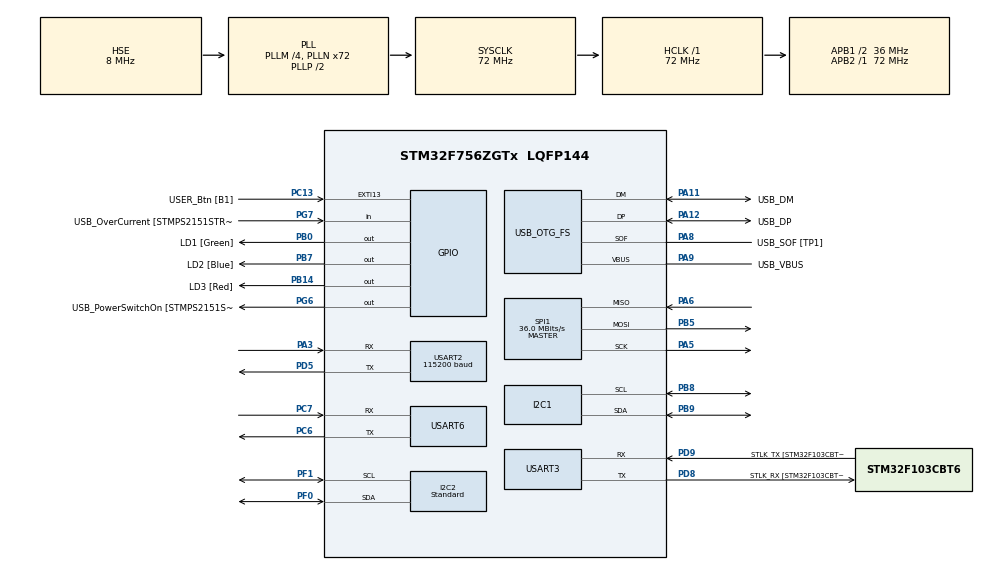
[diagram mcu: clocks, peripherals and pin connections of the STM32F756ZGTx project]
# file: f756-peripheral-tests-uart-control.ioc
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Dma.I2C1_RX.2.Direction=DMA_PERIPH_TO_MEMORY
Dma.I2C1_RX.2.FIFOMode=DMA_FIFOMODE_DISABLE
Dma.I2C1_RX.2.Instance=DMA1_Stream0
Dma.I2C1_RX.2.MemDataAlignment=DMA_MDATAALIGN_BYTE
Dma.I2C1_RX.2.MemInc=DMA_MINC_ENABLE
Dma.I2C1_RX.2.Mode=DMA_NORMAL
Dma.I2C1_RX.2.PeriphDataAlignment=DMA_PDATAALIGN_BYTE
Dma.I2C1_RX.2.PeriphInc=DMA_PINC_DISABLE
Dma.I2C1_RX.2.Priority=DMA_PRIORITY_LOW
Dma.I2C1_TX.3.Direction=DMA_MEMORY_TO_PERIPH
Dma.I2C1_TX.3.FIFOMode=DMA_FIFOMODE_DISABLE
Dma.I2C1_TX.3.Instance=DMA1_Stream6
Dma.I2C1_TX.3.MemDataAlignment=DMA_MDATAALIGN_BYTE
Dma.I2C1_TX.3.MemInc=DMA_MINC_ENABLE
Dma.I2C1_TX.3.Mode=DMA_NORMAL
Dma.I2C1_TX.3.PeriphDataAlignment=DMA_PDATAALIGN_BYTE
Dma.I2C1_TX.3.PeriphInc=DMA_PINC_DISABLE
Dma.I2C1_TX.3.Priority=DMA_PRIORITY_LOW
Dma.I2C2_RX.1.Direction=DMA_PERIPH_TO_MEMORY
Dma.I2C2_RX.1.FIFOMode=DMA_FIFOMODE_DISABLE
Dma.I2C2_RX.1.Instance=DMA1_Stream3
Dma.I2C2_RX.1.MemDataAlignment=DMA_MDATAALIGN_BYTE
Dma.I2C2_RX.1.MemInc=DMA_MINC_ENABLE
Dma.I2C2_RX.1.Mode=DMA_NORMAL
Dma.I2C2_RX.1.PeriphDataAlignment=DMA_PDATAALIGN_BYTE
Dma.I2C2_RX.1.PeriphInc=DMA_PINC_DISABLE
Dma.I2C2_RX.1.Priority=DMA_PRIORITY_LOW
Dma.I2C2_TX.0.Direction=DMA_MEMORY_TO_PERIPH
Dma.I2C2_TX.0.FIFOMode=DMA_FIFOMODE_DISABLE
Dma.I2C2_TX.0.Instance=DMA1_Stream7
Dma.I2C2_TX.0.MemDataAlignment=DMA_MDATAALIGN_BYTE
Dma.I2C2_TX.0.MemInc=DMA_MINC_ENABLE
Dma.I2C2_TX.0.Mode=DMA_NORMAL
Dma.I2C2_TX.0.PeriphDataAlignment=DMA_PDATAALIGN_BYTE
Dma.I2C2_TX.0.PeriphInc=DMA_PINC_DISABLE
Dma.I2C2_TX.0.Priority=DMA_PRIORITY_LOW
Dma.Request0=I2C2_TX
Dma.Request1=I2C2_RX
Dma.Request2=I2C1_RX
Dma.Request3=I2C1_TX
FREERTOS.Tasks01=defaultTask,24,128,StartDefaultTask,Default,NULL,Static,defaultTaskBuffer,defaultTaskControlBlock;UARTListenTask,8,128,StartUARTListenTask,Default,NULL,Static,UARTListenTaskBuffer,UARTListenTaskControlBlock;UARTTestTask,8,128,StartUARTTestTask,Default,NULL,Static,UARTTestTaskBuffer,UARTTestTaskControlBlock;I2CTestTask,8,128,StartI2CTestTask,Default,NULL,Static,I2CTestTaskBuffer,I2CTestTaskControlBlock;SPITestTask,8,128,StartSPITestTask,Default,NULL,Static,SPITestTaskBuffer,SPITestTaskControlBlock
FREERTOS.configUSE_NEWLIB_REENTRANT=1
I2C1.GeneralCallMode=I2C_GENERALCALL_ENABLE
I2C1.OwnAddress=0x0A
I2C1.Timing=0x00808CD2
I2C2.DualAddressMode=I2C_DUALADDRESS_DISABLE
I2C2.I2C_Speed_Mode=I2C_Standard
I2C2.OwnAddress=0x72
I2C2.Timing=0x00808CD2
Mcu.Family=STM32F7
Mcu.Name=STM32F756ZGTx
Mcu.Package=LQFP144
NVIC.DMA1_Stream0_IRQn=true\:5\:0\:false\:false\:true\:true\:false\:true\:true
NVIC.DMA1_Stream3_IRQn=true\:5\:0\:false\:false\:true\:true\:false\:true\:true
NVIC.DMA1_Stream6_IRQn=true\:5\:0\:false\:false\:true\:true\:false\:true\:true
NVIC.DMA1_Stream7_IRQn=true\:5\:0\:false\:false\:true\:true\:false\:true\:true
NVIC.EXTI15_10_IRQn=true\:5\:0\:false\:false\:true\:true\:true\:true\:true
NVIC.I2C1_ER_IRQn=true\:5\:0\:false\:false\:true\:true\:true\:true\:true
NVIC.I2C1_EV_IRQn=true\:5\:0\:false\:false\:true\:true\:true\:true\:true
NVIC.I2C2_ER_IRQn=true\:5\:0\:false\:false\:true\:true\:true\:true\:true
NVIC.I2C2_EV_IRQn=true\:5\:0\:false\:false\:true\:true\:true\:true\:true
NVIC.PriorityGroup=NVIC_PRIORITYGROUP_4
NVIC.TIM2_IRQn=true\:15\:0\:false\:false\:true\:false\:false\:true\:true
NVIC.TimeBase=TIM2_IRQn
NVIC.TimeBaseIP=TIM2
NVIC.USART6_IRQn=true\:5\:0\:false\:false\:true\:true\:true\:true\:true
PA1.GPIO_Label=RMII_REF_CLK [LAN8742A-CZ-TR_REFCLK0]
PA1.Signal=ETH_REF_CLK
PA10.GPIO_Label=USB_ID
PA10.Signal=USB_OTG_FS_ID
PA11.GPIO_Label=USB_DM
PA11.Mode=Device_Only
PA11.Signal=USB_OTG_FS_DM
PA12.GPIO_Label=USB_DP
PA12.Mode=Device_Only
PA12.Signal=USB_OTG_FS_DP
PA13.GPIO_Label=TMS
PA13.Mode=Serial_Wire
PA13.Signal=SYS_JTMS-SWDIO
PA14.GPIO_Label=TCK
PA14.Mode=Serial_Wire
PA14.Signal=SYS_JTCK-SWCLK
PA2.GPIO_Label=RMII_MDIO [LAN8742A-CZ-TR_MDIO]
PA2.Signal=ETH_MDIO
PA3.GPIO_PuPd=GPIO_NOPULL
PA3.Mode=Asynchronous
PA3.Signal=USART2_RX
PA5.Mode=Full_Duplex_Master
PA5.Signal=SPI1_SCK
PA6.Mode=Full_Duplex_Master
PA6.Signal=SPI1_MISO
PA7.GPIO_Label=RMII_CRS_DV [LAN8742A-CZ-TR_CRS_DV]
PA7.Signal=ETH_CRS_DV
PA8.GPIO_Label=USB_SOF [TP1]
PA8.Mode=Activate_SOF_FS
PA8.Signal=USB_OTG_FS_SOF
PA9.GPIO_Label=USB_VBUS
PA9.Mode=Activate_VBUS
PA9.Signal=USB_OTG_FS_VBUS
PB0.GPIO_Label=LD1 [Green]
PB0.Signal=GPIO_Output
PB13.GPIO_Label=RMII_TXD1 [LAN8742A-CZ-TR_TXD1]
PB13.Signal=ETH_TXD1
PB14.GPIO_Label=LD3 [Red]
PB14.Signal=GPIO_Output
PB3.GPIO_Label=SW0
PB3.Signal=SYS_JTDO-SWO
PB5.Mode=Full_Duplex_Master
PB5.Signal=SPI1_MOSI
PB7.GPIO_Label=LD2 [Blue]
PB7.Signal=GPIO_Output
PB8.GPIO_Pu=GPIO_PULLUP
PB8.Mode=I2C
PB8.Signal=I2C1_SCL
PB9.GPIO_Pu=GPIO_PULLUP
PB9.Mode=I2C
PB9.Signal=I2C1_SDA
PC1.GPIO_Label=RMII_MDC [LAN8742A-CZ-TR_MDC]
PC1.Signal=ETH_MDC
PC13.GPIO_Label=USER_Btn [B1]
PC13.Signal=GPXTI13
PC14/OSC32_IN.Mode=LSE-External-Oscillator
PC14/OSC32_IN.Signal=RCC_OSC32_IN
PC15/OSC32_OUT.Mode=LSE-External-Oscillator
PC15/OSC32_OUT.Signal=RCC_OSC32_OUT
PC4.GPIO_Label=RMII_RXD0 [LAN8742A-CZ-TR_RXD0]
PC4.Signal=ETH_RXD0
PC5.GPIO_Label=RMII_RXD1 [LAN8742A-CZ-TR_RXD1]
PC5.Signal=ETH_RXD1
PC6.Mode=Asynchronous
PC6.Signal=USART6_TX
PC7.Mode=Asynchronous
PC7.Signal=USART6_RX
PD5.GPIO_PuPd=GPIO_NOPULL
PD5.Mode=Asynchronous
PD5.Signal=USART2_TX
PD8.GPIO_Label=STLK_RX [STM32F103CBT6_PA3]
PD8.Mode=Asynchronous
PD8.Signal=USART3_TX
PD9.GPIO_Label=STLK_TX [STM32F103CBT6_PA2]
PD9.Mode=Asynchronous
PD9.Signal=USART3_RX
PF0.GPIO_Pu=GPIO_PULLUP
PF0.Mode=I2C
PF0.Signal=I2C2_SDA
PF1.GPIO_Pu=GPIO_PULLUP
PF1.Mode=I2C
PF1.Signal=I2C2_SCL
PG11.GPIO_Label=RMII_TX_EN [LAN8742A-CZ-TR_TXEN]
PG11.Signal=ETH_TX_EN
PG13.GPIO_Label=RMII_TXD0 [LAN8742A-CZ-TR_TXD0]
PG13.Signal=ETH_TXD0
PG6.GPIO_Label=USB_PowerSwitchOn [STMPS2151STR_EN]
PG6.Signal=GPIO_Output
PG7.GPIO_Label=USB_OverCurrent [STMPS2151STR_FAULT]
PG7.Signal=GPIO_Input
PH0/OSC_IN.GPIO_Label=MCO [STM32F103CBT6_PA8]
PH0/OSC_IN.Mode=HSE-External-Clock-Source
PH0/OSC_IN.Signal=RCC_OSC_IN
PH1/OSC_OUT.Mode=HSE-External-Clock-Source
PH1/OSC_OUT.Signal=RCC_OSC_OUT
ProjectManager.HeapSize=0x200
ProjectManager.StackSize=0x400
ProjectManager.TargetToolchain=STM32CubeIDE
RCC.48MHZClocksFreq_Value=24000000
RCC.AHBFreq_Value=72000000
RCC.APB1CLKDivider=RCC_HCLK_DIV2
RCC.APB1Freq_Value=36000000
RCC.APB1TimFreq_Value=72000000
RCC.APB2Freq_Value=72000000
RCC.APB2TimFreq_Value=72000000
RCC.CortexFreq_Value=72000000
RCC.HCLKFreq_Value=72000000
RCC.HSE_VALUE=8000000
RCC.HSI_VALUE=16000000
RCC.PLLM=4
RCC.PLLMUL=RCC_PLL_MUL9
RCC.PLLN=72
RCC.PLLQ=3
RCC.PRESCALERUSB=RCC_USBCLKSOURCE_PLL_DIV1_5
RCC.SYSCLKFreq_VALUE=72000000
RCC.SYSCLKSource=RCC_SYSCLKSOURCE_PLLCLK
RCC.SYSCLKSourceVirtual=RCC_SYSCLKSOURCE_PLLCLK
RCC.USBFreq_Value=48000000
RCC.VCOOutputFreq_Value=144000000
SPI1.CalculateBaudRate=36.0 MBits/s
SPI1.DataSize=SPI_DATASIZE_8BIT
SPI1.Direction=SPI_DIRECTION_2LINES
SPI1.Mode=SPI_MODE_MASTER
SPI1.NSSPMode=SPI_NSS_PULSE_DISABLE
SPI1.VirtualType=VM_MASTER
USART2.AutoBaudRateEnableParam=UART_ADVFEATURE_AUTOBAUDRATE_DISABLE
USART2.BaudRate=115200
USART2.MSBFirstParam=ADVFEATURE_MSBFIRST_DISABLE
USART2.VirtualMode-Asynchronous=VM_ASYNC
USART3.VirtualMode-Asynchronous=VM_ASYNC
USART6.VirtualMode-Asynchronous=VM_ASYNC
USB_OTG_FS.VirtualMode=Device_Only
VP_FREERTOS_VS_CMSIS_V2.Mode=CMSIS_V2
VP_SYS_VS_tim2.Mode=TIM2
board=NUCLEO-F756ZG

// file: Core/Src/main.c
/* USER CODE BEGIN Header */
/**
  ******************************************************************************
  * @file           : main.c
  * @brief          : Main program body
  ******************************************************************************
  * @attention
  *
  * Copyright (c) 2025 STMicroelectronics.
  * All rights reserved.
  *
  * This software is licensed under terms that can be found in the LICENSE file
  * in the root directory of this software component.
  * If no LICENSE file comes with this software, it is provided AS-IS.
  *
  ******************************************************************************
  */
/* USER CODE END Header */
#include "main.h"
#include "cmsis_os.h"

typedef StaticTask_t osStaticThreadDef_t;

I2C_HandleTypeDef hi2c1;
I2C_HandleTypeDef hi2c2;
DMA_HandleTypeDef hdma_i2c1_rx;
DMA_HandleTypeDef hdma_i2c1_tx;
DMA_HandleTypeDef hdma_i2c2_tx;
DMA_HandleTypeDef hdma_i2c2_rx;

SPI_HandleTypeDef hspi1;

UART_HandleTypeDef huart2;
UART_HandleTypeDef huart3;
UART_HandleTypeDef huart6;

PCD_HandleTypeDef hpcd_USB_OTG_FS;

/* Definitions for defaultTask */
osThreadId_t defaultTaskHandle;
uint32_t defaultTaskBuffer[ 128 ];
osStaticThreadDef_t defaultTaskControlBlock;
const osThreadAttr_t defaultTask_attributes = {
  .name = "defaultTask",
  .cb_mem = &defaultTaskControlBlock,
  .cb_size = sizeof(defaultTaskControlBlock),
  .stack_mem = &defaultTaskBuffer[0],
  .stack_size = sizeof(defaultTaskBuffer),
  .priority = (osPriority_t) osPriorityNormal,
};
/* Definitions for UARTListenTask */
osThreadId_t UARTListenTaskHandle;
uint32_t UARTListenTaskBuffer[ 128 ];
osStaticThreadDef_t UARTListenTaskControlBlock;
const osThreadAttr_t UARTListenTask_attributes = {
  .name = "UARTListenTask",
  .cb_mem = &UARTListenTaskControlBlock,
  .cb_size = sizeof(UARTListenTaskControlBlock),
  .stack_mem = &UARTListenTaskBuffer[0],
  .stack_size = sizeof(UARTListenTaskBuffer),
  .priority = (osPriority_t) osPriorityLow,
};
/* Definitions for UARTTestTask */
osThreadId_t UARTTestTaskHandle;
uint32_t UARTTestTaskBuffer[ 128 ];
osStaticThreadDef_t UARTTestTaskControlBlock;
const osThreadAttr_t UARTTestTask_attributes = {
  .name = "UARTTestTask",
  .cb_mem = &UARTTestTaskControlBlock,
  .cb_size = sizeof(UARTTestTaskControlBlock),
  .stack_mem = &UARTTestTaskBuffer[0],
  .stack_size = sizeof(UARTTestTaskBuffer),
  .priority = (osPriority_t) osPriorityLow,
};
/* Definitions for I2CTestTask */
osThreadId_t I2CTestTaskHandle;
uint32_t I2CTestTaskBuffer[ 128 ];
osStaticThreadDef_t I2CTestTaskControlBlock;
const osThreadAttr_t I2CTestTask_attributes = {
  .name = "I2CTestTask",
  .cb_mem = &I2CTestTaskControlBlock,
  .cb_size = sizeof(I2CTestTaskControlBlock),
  .stack_mem = &I2CTestTaskBuffer[0],
  .stack_size = sizeof(I2CTestTaskBuffer),
  .priority = (osPriority_t) osPriorityLow,
};
/* Definitions for SPITestTask */
osThreadId_t SPITestTaskHandle;
uint32_t SPITestTaskBuffer[ 128 ];
osStaticThreadDef_t SPITestTaskControlBlock;
const osThreadAttr_t SPITestTask_attributes = {
  .name = "SPITestTask",
  .cb_mem = &SPITestTaskControlBlock,
  .cb_size = sizeof(SPITestTaskControlBlock),
  .stack_mem = &SPITestTaskBuffer[0],
  .stack_size = sizeof(SPITestTaskBuffer),
  .priority = (osPriority_t) osPriorityLow,
};

void SystemClock_Config(void);
static void MX_GPIO_Init(void);
static void MX_DMA_Init(void);
static void MX_USART3_UART_Init(void);
static void MX_USB_OTG_FS_PCD_Init(void);
static void MX_USART2_UART_Init(void);
static void MX_I2C2_Init(void);
static void MX_I2C1_Init(void);
static void MX_SPI1_Init(void);
static void MX_USART6_UART_Init(void);
void StartDefaultTask(void *argument);
void StartUARTListenTask(void *argument);
void StartUARTTestTask(void *argument);
void StartI2CTestTask(void *argument);
void StartSPITestTask(void *argument);

int main(void)
{

  /* MCU Configuration--------------------------------------------------------*/

  /* Reset of all peripherals, Initializes the Flash interface and the Systick. */
  HAL_Init();

  /* Configure the system clock */
  SystemClock_Config();

  /* Initialize all configured peripherals */
  MX_GPIO_Init();
  MX_DMA_Init();
  MX_USART3_UART_Init();
  MX_USB_OTG_FS_PCD_Init();
  MX_USART2_UART_Init();
  MX_I2C2_Init();
  MX_I2C1_Init();
  MX_SPI1_Init();
  MX_USART6_UART_Init();
  /* USER CODE BEGIN 2 */
  serial_uart_initialize();
  /* USER CODE END 2 */

  /* Init scheduler */
  osKernelInitialize();

  /* Create the thread(s) */
  /* creation of defaultTask */
  defaultTaskHandle = osThreadNew(StartDefaultTask, NULL, &defaultTask_attributes);

  /* creation of UARTListenTask */
  UARTListenTaskHandle = osThreadNew(StartUARTListenTask, NULL, &UARTListenTask_attributes);

  /* creation of UARTTestTask */
  UARTTestTaskHandle = osThreadNew(StartUARTTestTask, NULL, &UARTTestTask_attributes);

  /* creation of I2CTestTask */
  I2CTestTaskHandle = osThreadNew(StartI2CTestTask, NULL, &I2CTestTask_attributes);

  /* creation of SPITestTask */
  SPITestTaskHandle = osThreadNew(StartSPITestTask, NULL, &SPITestTask_attributes);

  /* Start scheduler */
  osKernelStart();

  /* We should never get here as control is now taken by the scheduler */

  /* Infinite loop */
  while (1)
  {

  }
}

void SystemClock_Config(void)
{
  RCC_OscInitTypeDef RCC_OscInitStruct = {0};
  RCC_ClkInitTypeDef RCC_ClkInitStruct = {0};

  /** Configure LSE Drive Capability
  */
  HAL_PWR_EnableBkUpAccess();

  /** Configure the main internal regulator output voltage
  */
  __HAL_RCC_PWR_CLK_ENABLE();
  __HAL_PWR_VOLTAGESCALING_CONFIG(PWR_REGULATOR_VOLTAGE_SCALE3);

  /** Initializes the RCC Oscillators according to the specified parameters
  * in the RCC_OscInitTypeDef structure.
  */
  RCC_OscInitStruct.OscillatorType = RCC_OSCILLATORTYPE_HSE;
  RCC_OscInitStruct.HSEState = RCC_HSE_BYPASS;
  RCC_OscInitStruct.PLL.PLLState = RCC_PLL_ON;
  RCC_OscInitStruct.PLL.PLLSource = RCC_PLLSOURCE_HSE;
  RCC_OscInitStruct.PLL.PLLM = 4;
  RCC_OscInitStruct.PLL.PLLN = 72;
  RCC_OscInitStruct.PLL.PLLP = RCC_PLLP_DIV2;
  RCC_OscInitStruct.PLL.PLLQ = 3;
  if (HAL_RCC_OscConfig(&RCC_OscInitStruct) != HAL_OK)
  {
    Error_Handler();
  }

  /** Initializes the CPU, AHB and APB buses clocks
  */
  RCC_ClkInitStruct.ClockType = RCC_CLOCKTYPE_HCLK|RCC_CLOCKTYPE_SYSCLK
                              |RCC_CLOCKTYPE_PCLK1|RCC_CLOCKTYPE_PCLK2;
  RCC_ClkInitStruct.SYSCLKSource = RCC_SYSCLKSOURCE_PLLCLK;
  RCC_ClkInitStruct.AHBCLKDivider = RCC_SYSCLK_DIV1;
  RCC_ClkInitStruct.APB1CLKDivider = RCC_HCLK_DIV2;
  RCC_ClkInitStruct.APB2CLKDivider = RCC_HCLK_DIV1;

  if (HAL_RCC_ClockConfig(&RCC_ClkInitStruct, FLASH_LATENCY_2) != HAL_OK)
  {
    Error_Handler();
  }
}

static void MX_I2C1_Init(void)
{

  hi2c1.Instance = I2C1;
  hi2c1.Init.Timing = 0x00808CD2;
  hi2c1.Init.OwnAddress1 = 20;
  hi2c1.Init.AddressingMode = I2C_ADDRESSINGMODE_7BIT;
  hi2c1.Init.DualAddressMode = I2C_DUALADDRESS_DISABLE;
  hi2c1.Init.OwnAddress2 = 0;
  hi2c1.Init.OwnAddress2Masks = I2C_OA2_NOMASK;
  hi2c1.Init.GeneralCallMode = I2C_GENERALCALL_ENABLE;
  hi2c1.Init.NoStretchMode = I2C_NOSTRETCH_DISABLE;
  if (HAL_I2C_Init(&hi2c1) != HAL_OK)
  {
    Error_Handler();
  }

  /** Configure Analogue filter
  */
  if (HAL_I2CEx_ConfigAnalogFilter(&hi2c1, I2C_ANALOGFILTER_ENABLE) != HAL_OK)
  {
    Error_Handler();
  }

  /** Configure Digital filter
  */
  if (HAL_I2CEx_ConfigDigitalFilter(&hi2c1, 0) != HAL_OK)
  {
    Error_Handler();
  }

}

static void MX_I2C2_Init(void)
{

  hi2c2.Instance = I2C2;
  hi2c2.Init.Timing = 0x00808CD2;
  hi2c2.Init.OwnAddress1 = 228;
  hi2c2.Init.AddressingMode = I2C_ADDRESSINGMODE_7BIT;
  hi2c2.Init.DualAddressMode = I2C_DUALADDRESS_DISABLE;
  hi2c2.Init.OwnAddress2 = 0;
  hi2c2.Init.OwnAddress2Masks = I2C_OA2_NOMASK;
  hi2c2.Init.GeneralCallMode = I2C_GENERALCALL_DISABLE;
  hi2c2.Init.NoStretchMode = I2C_NOSTRETCH_DISABLE;
  if (HAL_I2C_Init(&hi2c2) != HAL_OK)
  {
    Error_Handler();
  }

  /** Configure Analogue filter
  */
  if (HAL_I2CEx_ConfigAnalogFilter(&hi2c2, I2C_ANALOGFILTER_ENABLE) != HAL_OK)
  {
    Error_Handler();
  }

  /** Configure Digital filter
  */
  if (HAL_I2CEx_ConfigDigitalFilter(&hi2c2, 0) != HAL_OK)
  {
    Error_Handler();
  }

}

static void MX_SPI1_Init(void)
{

  /* SPI1 parameter configuration*/
  hspi1.Instance = SPI1;
  hspi1.Init.Mode = SPI_MODE_MASTER;
  hspi1.Init.Direction = SPI_DIRECTION_2LINES;
  hspi1.Init.DataSize = SPI_DATASIZE_8BIT;
  hspi1.Init.CLKPolarity = SPI_POLARITY_LOW;
  hspi1.Init.CLKPhase = SPI_PHASE_1EDGE;
  hspi1.Init.NSS = SPI_NSS_SOFT;
  hspi1.Init.BaudRatePrescaler = SPI_BAUDRATEPRESCALER_2;
  hspi1.Init.FirstBit = SPI_FIRSTBIT_MSB;
  hspi1.Init.TIMode = SPI_TIMODE_DISABLE;
  hspi1.Init.CRCCalculation = SPI_CRCCALCULATION_DISABLE;
  hspi1.Init.CRCPolynomial = 7;
  hspi1.Init.CRCLength = SPI_CRC_LENGTH_DATASIZE;
  hspi1.Init.NSSPMode = SPI_NSS_PULSE_DISABLE;
  if (HAL_SPI_Init(&hspi1) != HAL_OK)
  {
    Error_Handler();
  }

}

static void MX_USART2_UART_Init(void)
{

  huart2.Instance = USART2;
  huart2.Init.BaudRate = 115200;
  huart2.Init.WordLength = UART_WORDLENGTH_8B;
  huart2.Init.StopBits = UART_STOPBITS_1;
  huart2.Init.Parity = UART_PARITY_NONE;
  huart2.Init.Mode = UART_MODE_TX_RX;
  huart2.Init.HwFlowCtl = UART_HWCONTROL_NONE;
  huart2.Init.OverSampling = UART_OVERSAMPLING_16;
  huart2.Init.OneBitSampling = UART_ONE_BIT_SAMPLE_DISABLE;
  huart2.AdvancedInit.AdvFeatureInit = UART_ADVFEATURE_NO_INIT;
  if (HAL_UART_Init(&huart2) != HAL_OK)
  {
    Error_Handler();
  }

}

static void MX_USART3_UART_Init(void)
{

  huart3.Instance = USART3;
  huart3.Init.BaudRate = 115200;
  huart3.Init.WordLength = UART_WORDLENGTH_8B;
  huart3.Init.StopBits = UART_STOPBITS_1;
  huart3.Init.Parity = UART_PARITY_NONE;
  huart3.Init.Mode = UART_MODE_TX_RX;
  huart3.Init.HwFlowCtl = UART_HWCONTROL_NONE;
  huart3.Init.OverSampling = UART_OVERSAMPLING_16;
  huart3.Init.OneBitSampling = UART_ONE_BIT_SAMPLE_DISABLE;
  huart3.AdvancedInit.AdvFeatureInit = UART_ADVFEATURE_NO_INIT;
  if (HAL_UART_Init(&huart3) != HAL_OK)
  {
    Error_Handler();
  }

}

static void MX_USART6_UART_Init(void)
{

  huart6.Instance = USART6;
  huart6.Init.BaudRate = 115200;
  huart6.Init.WordLength = UART_WORDLENGTH_8B;
  huart6.Init.StopBits = UART_STOPBITS_1;
  huart6.Init.Parity = UART_PARITY_NONE;
  huart6.Init.Mode = UART_MODE_TX_RX;
  huart6.Init.HwFlowCtl = UART_HWCONTROL_NONE;
  huart6.Init.OverSampling = UART_OVERSAMPLING_16;
  huart6.Init.OneBitSampling = UART_ONE_BIT_SAMPLE_DISABLE;
  huart6.AdvancedInit.AdvFeatureInit = UART_ADVFEATURE_NO_INIT;
  if (HAL_UART_Init(&huart6) != HAL_OK)
  {
    Error_Handler();
  }

}

static void MX_USB_OTG_FS_PCD_Init(void)
{

  hpcd_USB_OTG_FS.Instance = USB_OTG_FS;
  hpcd_USB_OTG_FS.Init.dev_endpoints = 6;
  hpcd_USB_OTG_FS.Init.speed = PCD_SPEED_FULL;
  hpcd_USB_OTG_FS.Init.dma_enable = DISABLE;
  hpcd_USB_OTG_FS.Init.phy_itface = PCD_PHY_EMBEDDED;
  hpcd_USB_OTG_FS.Init.Sof_enable = ENABLE;
  hpcd_USB_OTG_FS.Init.low_power_enable = DISABLE;
  hpcd_USB_OTG_FS.Init.lpm_enable = DISABLE;
  hpcd_USB_OTG_FS.Init.vbus_sensing_enable = ENABLE;
  hpcd_USB_OTG_FS.Init.use_dedicated_ep1 = DISABLE;
  if (HAL_PCD_Init(&hpcd_USB_OTG_FS) != HAL_OK)
  {
    Error_Handler();
  }

}

static void MX_DMA_Init(void)
{

  /* DMA controller clock enable */
  __HAL_RCC_DMA1_CLK_ENABLE();

  /* DMA interrupt init */
  /* DMA1_Stream0_IRQn interrupt configuration */
  HAL_NVIC_SetPriority(DMA1_Stream0_IRQn, 5, 0);
  HAL_NVIC_EnableIRQ(DMA1_Stream0_IRQn);
  /* DMA1_Stream3_IRQn interrupt configuration */
  HAL_NVIC_SetPriority(DMA1_Stream3_IRQn, 5, 0);
  HAL_NVIC_EnableIRQ(DMA1_Stream3_IRQn);
  /* DMA1_Stream6_IRQn interrupt configuration */
  HAL_NVIC_SetPriority(DMA1_Stream6_IRQn, 5, 0);
  HAL_NVIC_EnableIRQ(DMA1_Stream6_IRQn);
  /* DMA1_Stream7_IRQn interrupt configuration */
  HAL_NVIC_SetPriority(DMA1_Stream7_IRQn, 5, 0);
  HAL_NVIC_EnableIRQ(DMA1_Stream7_IRQn);

}

static void MX_GPIO_Init(void)
{
  GPIO_InitTypeDef GPIO_InitStruct = {0};

  /* GPIO Ports Clock Enable */
  __HAL_RCC_GPIOC_CLK_ENABLE();
  __HAL_RCC_GPIOF_CLK_ENABLE();
  __HAL_RCC_GPIOH_CLK_ENABLE();
  __HAL_RCC_GPIOA_CLK_ENABLE();
  __HAL_RCC_GPIOB_CLK_ENABLE();
  __HAL_RCC_GPIOD_CLK_ENABLE();
  __HAL_RCC_GPIOG_CLK_ENABLE();

  /*Configure GPIO pin Output Level */
  HAL_GPIO_WritePin(GPIOB, LD1_Pin|LD3_Pin|LD2_Pin, GPIO_PIN_RESET);

  /*Configure GPIO pin Output Level */
  HAL_GPIO_WritePin(USB_PowerSwitchOn_GPIO_Port, USB_PowerSwitchOn_Pin, GPIO_PIN_RESET);

  /*Configure GPIO pin : USER_Btn_Pin */
  GPIO_InitStruct.Pin = USER_Btn_Pin;
  GPIO_InitStruct.Mode = GPIO_MODE_IT_RISING;
  GPIO_InitStruct.Pull = GPIO_NOPULL;
  HAL_GPIO_Init(USER_Btn_GPIO_Port, &GPIO_InitStruct);

  /*Configure GPIO pins : RMII_MDC_Pin RMII_RXD0_Pin RMII_RXD1_Pin */
  GPIO_InitStruct.Pin = RMII_MDC_Pin|RMII_RXD0_Pin|RMII_RXD1_Pin;
  GPIO_InitStruct.Mode = GPIO_MODE_AF_PP;
  GPIO_InitStruct.Pull = GPIO_NOPULL;
  GPIO_InitStruct.Speed = GPIO_SPEED_FREQ_VERY_HIGH;
  GPIO_InitStruct.Alternate = GPIO_AF11_ETH;
  HAL_GPIO_Init(GPIOC, &GPIO_InitStruct);

  /*Configure GPIO pins : RMII_REF_CLK_Pin RMII_MDIO_Pin RMII_CRS_DV_Pin */
  GPIO_InitStruct.Pin = RMII_REF_CLK_Pin|RMII_MDIO_Pin|RMII_CRS_DV_Pin;
  GPIO_InitStruct.Mode = GPIO_MODE_AF_PP;
  GPIO_InitStruct.Pull = GPIO_NOPULL;
  GPIO_InitStruct.Speed = GPIO_SPEED_FREQ_VERY_HIGH;
  GPIO_InitStruct.Alternate = GPIO_AF11_ETH;
  HAL_GPIO_Init(GPIOA, &GPIO_InitStruct);

  /*Configure GPIO pins : LD1_Pin LD3_Pin LD2_Pin */
  GPIO_InitStruct.Pin = LD1_Pin|LD3_Pin|LD2_Pin;
  GPIO_InitStruct.Mode = GPIO_MODE_OUTPUT_PP;
  GPIO_InitStruct.Pull = GPIO_NOPULL;
  GPIO_InitStruct.Speed = GPIO_SPEED_FREQ_LOW;
  HAL_GPIO_Init(GPIOB, &GPIO_InitStruct);

  /*Configure GPIO pin : RMII_TXD1_Pin */
  GPIO_InitStruct.Pin = RMII_TXD1_Pin;
  GPIO_InitStruct.Mode = GPIO_MODE_AF_PP;
  GPIO_InitStruct.Pull = GPIO_NOPULL;
  GPIO_InitStruct.Speed = GPIO_SPEED_FREQ_VERY_HIGH;
  GPIO_InitStruct.Alternate = GPIO_AF11_ETH;
  HAL_GPIO_Init(RMII_TXD1_GPIO_Port, &GPIO_InitStruct);

  /*Configure GPIO pin : USB_PowerSwitchOn_Pin */
  GPIO_InitStruct.Pin = USB_PowerSwitchOn_Pin;
  GPIO_InitStruct.Mode = GPIO_MODE_OUTPUT_PP;
  GPIO_InitStruct.Pull = GPIO_NOPULL;
  GPIO_InitStruct.Speed = GPIO_SPEED_FREQ_LOW;
  HAL_GPIO_Init(USB_PowerSwitchOn_GPIO_Port, &GPIO_InitStruct);

  /*Configure GPIO pin : USB_OverCurrent_Pin */
  GPIO_InitStruct.Pin = USB_OverCurrent_Pin;
  GPIO_InitStruct.Mode = GPIO_MODE_INPUT;
  GPIO_InitStruct.Pull = GPIO_NOPULL;
  HAL_GPIO_Init(USB_OverCurrent_GPIO_Port, &GPIO_InitStruct);

  /*Configure GPIO pins : RMII_TX_EN_Pin RMII_TXD0_Pin */
  GPIO_InitStruct.Pin = RMII_TX_EN_Pin|RMII_TXD0_Pin;
  GPIO_InitStruct.Mode = GPIO_MODE_AF_PP;
  GPIO_InitStruct.Pull = GPIO_NOPULL;
  GPIO_InitStruct.Speed = GPIO_SPEED_FREQ_VERY_HIGH;
  GPIO_InitStruct.Alternate = GPIO_AF11_ETH;
  HAL_GPIO_Init(GPIOG, &GPIO_InitStruct);

  /* EXTI interrupt init*/
  HAL_NVIC_SetPriority(EXTI15_10_IRQn, 5, 0);
  HAL_NVIC_EnableIRQ(EXTI15_10_IRQn);

}

void StartDefaultTask(void *argument)
{
  /* USER CODE BEGIN 5 */
  /* Infinite loop */
  for(;;)
  {
	  vTaskDelay(pdMS_TO_TICKS(10));
  }
  /* USER CODE END 5 */
}

void StartUARTListenTask(void *argument)
{
  /* USER CODE BEGIN StartUARTListenTask */
	test_listener_task_loop();
  /* USER CODE END StartUARTListenTask */
}

void StartUARTTestTask(void *argument)
{
  /* USER CODE BEGIN StartUARTTestTask */
  /* Infinite loop */
	test_task_loop(&test_defs[TESTIDX_UART]);
  /* USER CODE END StartUARTTestTask */
}

void StartI2CTestTask(void *argument)
{
  /* USER CODE BEGIN StartI2CTestTask */
	test_task_loop(&test_defs[TESTIDX_I2C]);
  /* USER CODE END StartI2CTestTask */
}

void StartSPITestTask(void *argument)
{
  /* USER CODE BEGIN StartSPITestTask */
	test_task_loop(&test_defs[TESTIDX_SPI]);
  /* USER CODE END StartSPITestTask */
}

void HAL_TIM_PeriodElapsedCallback(TIM_HandleTypeDef *htim)
{
  if (htim->Instance == TIM2)
  {
    HAL_IncTick();
  }
}

void Error_Handler(void)
{
  __disable_irq();
  while (1)
  {
  }
}
